# IWRL6432 register map
File version: 1.0
CPU: CM4 1.0, other endian, MPU, FPU, 3 interrupt priority bits
Registers are 32-bit, read-write, reset 0x0 unless marked. A register's access mark holds for its fields unless they carry their own. Offsets are from the block's base; [hi:lo] are bit positions; {n}, {i} and the like mark numbered series; <NAME> marks a mode.

## APP_SPI_0 — APP_SPI
Base 0x53F7F400
Same registers: APP_SPI_1 0x57F7F400
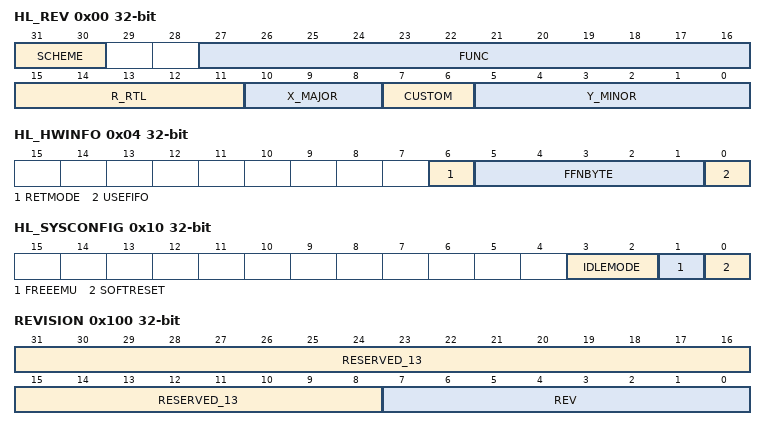
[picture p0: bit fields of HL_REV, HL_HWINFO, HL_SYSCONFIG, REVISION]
0x00 HL_REV — IP Revision Identifier (X.Y.R) Used by software to track features bugs and compatibility
  [31:30] SCHEME — [31:30] Used to distinguish between old scheme and current - (RO )
  [27:16] FUNC — [27:16] Function indicates a software compatible module family If there is no level of software compatibility a new Func number [and hence REVISION] should be assigned - (RO )
  [15:11] R_RTL — [15:11] RTL Version [R] maintained by IP design owner RTL follows a numbering such as XYRZ which are explained in this table R changes ONLY when: [1] PDS uploads occur which may have been due to spec changes [2] Bug fixes occur [3] Resets to '0' when X or Y changes Design team has an internal 'Z' [customer invisible] number which increments on every drop that happens due to DV and RTL updates Z resets to 0 when R increments - (RO )
  [10:8] X_MAJOR — [10:8] Major Revision [X] maintained by IP specification owner X changes ONLY when: [1] There is a major feature addition An example would be adding Master Mode to Utopia Level2 The Func field [or Class/Type in old PID format] will remain the same X does NOT change due to: [1] Bug fixes [2] Change in feature parameters - (RO )
  [7:6] CUSTOM — [7:6] Indicates a special version for a particular device Consequence of use may avoid use of standard Chip Support Library [CSL] / Drivers - (RO )
  [5:0] Y_MINOR — [5:0] Minor Revision [Y] maintained by IP specification owner Y changes ONLY when: [1] Features are scaled [up or down] Flexibility exists in that this feature scalability may either be represented in the Y change or a specific register in the IP that indicates which features are exactly available [2] When feature creeps from Is-Not list to Is list But this may not be the case once it sees silicon; in which case X will change Y does NOT change due to: [1] Bug fixes [2] Typos or clarifications [3] major functional/feature change/addition/deletion Instead these changes may be reflected via R S X as applicable Spec owner maintains a customer-invisible number 'S' which changes due to: [1] Typos/clarifications [2] Bug documentation Note that this bug is not due to a spec change but due to implementation Nevertheless the spec tracks the IP bugs An RTL release [say for silicon PG11] that occurs due to bug fix should document the corresponding spec number [XYS] in its release notes - (RO )
0x04 HL_HWINFO — Information about the IP module's hardware configuration i.e. typically the module's HDL generics (if any). Actual field format and encoding is up to the module's designer to decide.
  [6] RETMODE — [6:6] This bit field indicates whether the retention mode is supported using the pin PIRFFRET - (RO )
  [5:1] FFNBYTE — [5:1] FIFO number of byte generic parameter This register defines the value of FFNBYTE generic parameter only MSB bits from 8 down to 4 are taken into account - (RO )
  [0] USEFIFO — [0:0] Use of a FIFO enable: This bit field indicates if a FIFO is integrated within controller design with its management - (RO )
0x10 HL_SYSCONFIG — Clock management configuration
  [3:2] IDLEMODE — [3:2] Configuration of the local target state management mode By definition target can handle read/write transaction as long as it is out of IDLE state - (RW )
  [1] FREEEMU — [1:1] Sensitivity to emulation [debug] suspend input signal - (RW )
  [0] SOFTRESET — [0:0] Software reset [Optional] - (RW )
0x100 REVISION — This register contains the hard coded RTL revision number.
  [31:8] RESERVED_13 — [31:8] Reads returns 0 - (RO )
  [7:0] REV — [7:0] IP revision [7:4] Major revision [3:0] Minor revision Examples: 0x10 for 10 0x21 for 21 - (RO
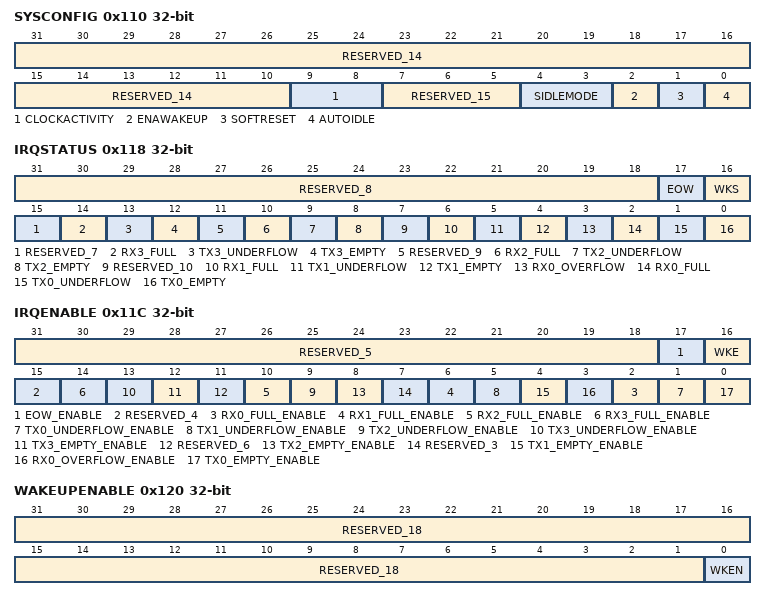
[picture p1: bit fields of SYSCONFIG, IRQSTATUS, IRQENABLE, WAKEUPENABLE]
0x110 SYSCONFIG — This register allows controlling various parameters of the OCP interface.
  [31:10] RESERVED_14 — [31:10] Reads returns 0 - (RO )
  [9:8] CLOCKACTIVITY — [9:8] Clocks activity during wake up mode period - (RW )
  [7:5] RESERVED_15 — [7:5] Reads returns 0 - (RO )
  [4:3] SIDLEMODE — [4:3] Power management - (RW )
  [2] ENAWAKEUP — [2:2] WakeUp feature control - (RW )
  [1] SOFTRESET — [1:1] Software reset During reads it always returns 0 - (RW )
  [0] AUTOIDLE — [0:0] Internal OCP Clock gating strategy - (RW )
0x114 SYSSTATUS — This register provides status information about the module excluding the interrupt status information
  [0] RESETDONE — [0:0] Internal Reset Monitoring - (RO )
0x118 IRQSTATUS — The interrupt status regroups all the status of the module internal events that can generate an interrupt
  [31:18] RESERVED_8 — [31:18] Reads returns 0 - (RO )
  [17] EOW — [17:17] End of word count event when a channel is enabled using the FIFO buffer and the channel had sent the number of SPI word defined by MCSPI_XFERLEVEL[WCNT] - (RW )
  [16] WKS — [16:16] Wake Up event in slave mode when an active control signal is detected on the SPIEN line programmed in the field MCSPI_CH0CONF[SPIENSLV] - (RW )
  [15] RESERVED_7 — [15:15] Reads returns 0 - (RO )
  [14] RX3_FULL — [14:14] Receiver register is full or almost full Only when Channel 3 is enabled - (RW )
  [13] TX3_UNDERFLOW — [13:13] Transmitter register underflow Only when Channel 3 is enabled The transmitter register is empty [not updated by Host or DMA with new data] before its time slot assignment Exception: No TX_underflow event when no data has been loaded into the transmitter register since channel has been enabled - (RW )
  [12] TX3_EMPTY — [12:12] Transmitter register is empty or almost empty Note: Enabling the channel automatically rises this event - (RW )
  [11] RESERVED_9 — [11:11] Reads returns 0 - (RO )
  [10] RX2_FULL — [10:10] Receiver register full or almost full Channel 2 - (RW )
  [9] TX2_UNDERFLOW — [9:9] Transmitter register underflow Channel 2 - (RW )
  [8] TX2_EMPTY — [8:8] Transmitter register empty or almost empty Channel 2 - (RW )
  [7] RESERVED_10 — [7:7] Reads returns 0 - (RO )
  [6] RX1_FULL — [6:6] Receiver register full or almost full Channel 1 - (RW )
  [5] TX1_UNDERFLOW — [5:5] Transmitter register underflow Channel 1 - (RW )
  [4] TX1_EMPTY — [4:4] Transmitter register empty or almost empty Channel 1 - (RW )
  [3] RX0_OVERFLOW — [3:3] Receiver register overflow [slave mode only] Channel 0 - (RW )
  [2] RX0_FULL — [2:2] Receiver register full or almost full Channel 0 - (RW )
  [1] TX0_UNDERFLOW — [1:1] Transmitter register underflow Channel 0 - (RW )
  [0] TX0_EMPTY — [0:0] Transmitter register empty or almost empty Channel 0 - (RW )
0x11C IRQENABLE — This register allows to enable/disable the module internal sources of interrupt on an event-by-event basis.
  [31:18] RESERVED_5 — [31:18] Reads return 0 - (RO )
  [17] EOW_ENABLE — [17:17] End of Word count Interrupt Enable - (RW )
  [16] WKE — [16:16] Wake Up event interrupt Enable in slave mode when an active control signal is detected on the SPIEN line programmed in the field MCSPI_CH0CONF[SPIENSLV] - (RW )
  [15] RESERVED_4 — [15:15] Reads returns 0 - (RO )
  [4n+2] RX{n}_FULL_ENABLE (n=0..3) — [{4n+2}:{4n+2}] Receiver register Full Interrupt Enable Ch {n} - (RW )
  [4n+1] TX{n}_UNDERFLOW_ENABLE (n=0..3) — [{4n+1}:{4n+1}] Transmitter register Underflow Interrupt Enable Ch {n} - (RW )
  [12] TX3_EMPTY_ENABLE — [12:12] Transmitter register Empty Interrupt Enable Ch3 - (RW )
  [11] RESERVED_6 — [11:11] Reads return 0 - (RO )
  [8] TX2_EMPTY_ENABLE — [8:8] Transmitter register Empty Interrupt Enable Ch 2 - (RW )
  [7] RESERVED_3 — [7:7] Reads return 0 - (RO )
  [4] TX1_EMPTY_ENABLE — [4:4] Transmitter register Empty Interrupt Enable Ch 1 - (RW )
  [3] RX0_OVERFLOW_ENABLE — [3:3] Receiver register Overflow Interrupt Enable Ch 0 - (RW )
  [0] TX0_EMPTY_ENABLE — [0:0] Transmitter register Empty Interrupt Enable Ch 0 - (RW )
0x120 WAKEUPENABLE — The wakeup enable register allows to enable/disable the module internal sources of wakeup on event-by-event basis.
  [31:1] RESERVED_18 — [31:1] Reads returns 0 - (RO )
  [0] WKEN — [0:0] WakeUp functionality in slave mode when an active control signal is detected on the SPIEN line programmed in the field MCSPI_CH0CONF[SPIENSLV] - (RW )
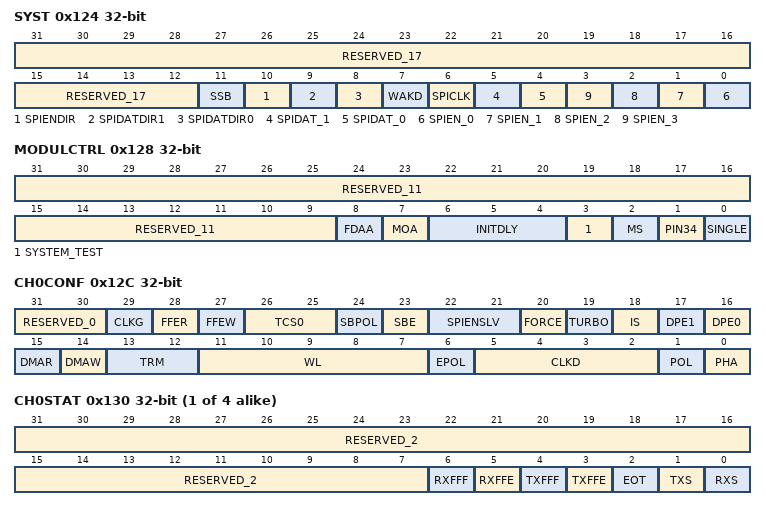
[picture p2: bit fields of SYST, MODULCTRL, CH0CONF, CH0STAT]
0x124 SYST — This register is used to check the correctness of the system interconnect either internally to peripheral bus or externally to device IO pads when the module is configured in system test (SYSTEST) mode.
  [31:12] RESERVED_17 — [31:12] Reads returns 0 - (RO )
  [11] SSB — [11:11] Set status bit - (RW )
  [10] SPIENDIR — [10:10] Set the direction of the SPIEN[3:0] lines and SPICLK line - (RW )
  [9] SPIDATDIR1 — [9:9] Set the direction of the SPIDAT[1] - (RW )
  [8] SPIDATDIR0 — [8:8] Set the direction of the SPIDAT[0] - (RW )
  [7] WAKD — [7:7] SWAKEUP output [signal data value of internal signal to system] The signal is driven high or low according to the value written into this register bit - (RW )
  [6] SPICLK — [6:6] SPICLK line [signal data value] If MCSPI_SYST[SPIENDIR] = 1 [input mode direction] this bit returns the value on the CLKSPI line [high or low] and a write into this bit has no effect If MCSPI_SYST[SPIENDIR] = 0 [output mode direction] the CLKSPI line is driven high or low according to the value written into this register - (RW )
  [5] SPIDAT_1 — [5:5] SPIDAT[1] line [signal data value] If MCSPI_SYST[SPIDATDIR1] = 0 [output mode direction] the SPIDAT[1] line is driven high or low according to the value written into this register If MCSPI_SYST[SPIDATDIR1] = 1 [input mode direction] this bit returns the value on the SPIDAT[1] line [high or low] and a write into this bit has no effect - (RW )
  [4] SPIDAT_0 — [4:4] SPIDAT[0] line [signal data value] If MCSPI_SYST[SPIDATDIR0] = 0 [output mode direction] the SPIDAT[0] line is driven high or low according to the value written into this register If MCSPI_SYST[SPIDATDIR0] = 1 [input mode direction] this bit returns the value on the SPIDAT[0] line [high or low] and a write into this bit has no effect - (RW )
  [n] SPIEN_{n} (n=0..3) — [{n}:{n}] SPIEN[{n}] line [signal data value] If MCSPI_SYST[SPIENDIR] = 0 [output mode direction] the SPIENT[{n}] line is driven high or low according to the value written into this register If MCSPI_SYST[SPIENDIR] = 1 [input mode direction] this bit returns the value on the SPIEN[{n}] line [high or low] and a write into this bit has no effect - (RW )
0x128 MODULCTRL — This register is dedicated to the configuration of the serial port interface.
  [31:9] RESERVED_11 — [31:9] Reads returns 0 - (RO )
  [8] FDAA — [8:8] FIFO DMA Address 256-bit aligned This register is used when a FIFO is managed by the module and DMA connected to the controller provides only 256 bit aligned address If this bit is set the enabled channel which uses the FIFO has its datas managed through MCSPI_DAFTX and MCSPI_DAFRX registers instead of MCSPI_TX[i] and MCSPI_RX[i] registers - (RW )
  [7] MOA — [7:7] Multiple word ocp access: This register can only be used when a channel is enabled using a FIFO It allows the system to perform multiple SPI word access for a single 32-bit OCP word access This is possible for WL < 16 - (RW )
  [6:4] INITDLY — [6:4] Initial spi delay for first transfer: This register is an option only available in SINGLE master mode The controller waits for a delay to transmit the first spi word after channel enabled and corresponding TX register filled This Delay is based on SPI output frequency clock No clock output provided to the boundary and chip select is not active in 4 pin mode within this period - (RW )
  [3] SYSTEM_TEST — [3:3] Enables the system test mode - (RW )
  [2] MS — [2:2] Master/ Slave - (RW )
  [1] PIN34 — [1:1] Pin mode selection: This register is used to configure the SPI pin mode in master or slave mode If asserted the controller only use SIMOSOMI and SPICLK clock pin for spi transfers - (RW )
  [0] SINGLE — [0:0] Single channel / Multi Channel [master mode only] - (RW )
0x12C CH0CONF — This register is dedicated to the configuration of the channel 0
  [31:30] RESERVED_0 — [31:30] read returns 0 - (RO )
  [29] CLKG — [29:29] Clock divider granularity This register defines the granularity of channel clock divider: power of two or one clock cycle granularity When this bit is set the register MCSPI_CHCTRL[EXTCLK] must be configured to reach a maximum of 4096 clock divider ratio Then The clock divider ratio is a concatenation of MCSPI_CHCONF[CLKD] and MCSPI_CHCTRL[EXTCLK] values - (RW )
  [28] FFER — [28:28] FIFO enabled for receive:Only one channel can have this bit field set - (RW )
  [27] FFEW — [27:27] FIFO enabled for Transmit:Only one channel can have this bit field set - (RW )
  [26:25] TCS0 — [26:25] Chip Select Time Control This 2-bits field defines the number of interface clock cycles between CS toggling and first or last edge of SPI clock - (RW )
  [24] SBPOL — [24:24] Start bit polarity - (RW )
  [23] SBE — [23:23] Start bit enable for SPI transfer - (RW )
  [22:21] SPIENSLV — [22:21] Channel 0 only and slave mode only: SPI slave select signal detection Reserved bits for other cases - (RW )
  [20] FORCE — [20:20] Manual SPIEN assertion to keep SPIEN active between SPI words [single channel master mode only] - (RW )
  [19] TURBO — [19:19] Turbo mode - (RW )
  [18] IS — [18:18] Input Select - (RW )
  [17] DPE1 — [17:17] Transmission Enable for data line 1 [SPIDATAGZEN[1]] - (RW )
  [16] DPE0 — [16:16] Transmission Enable for data line 0 [SPIDATAGZEN[0]] - (RW )
  [15] DMAR — [15:15] DMA Read request The DMA Read request line is asserted when the channel is enabled and a new data is available in the receive register of the channel The DMA Read request line is deasserted on read completion of the receive register of the channel - (RW )
  [14] DMAW — [14:14] DMA Write request The DMA Write request line is asserted when The channel is enabled and the transmitter register of the channel is empty The DMA Write request line is deasserted on load completion of the transmitter register of the channel - (RW )
  [13:12] TRM — [13:12] Transmit/Receive modes - (RW )
  [11:7] WL — [11:7] SPI word length - (RW )
  [6] EPOL — [6:6] SPIEN polarity - (RW )
  [5:2] CLKD — [5:2] Frequency divider for SPICLK [only when the module is a Master SPI device] A programmable clock divider divides the SPI reference clock [CLKSPIREF] with a 4-bit value and results in a new clock SPICLK available to shift-in and shift-out data By default the clock divider ratio has a power of two granularity when MCSPI_CHCONF[CLKG] is cleared Otherwise this register is the 4 LSB bit of a 12-bit register concatenated with clock divider extension MCSPI_CHCTRL[EXTCLK] registerThe value description below defines the clock ratio when MCSPI_CHCONF[CLKG] is set to 0 - (RW )
  [1] POL — [1:1] SPICLK polarity - (RW )
  [0] PHA — [0:0] SPICLK phase - (RW )
{0x130+0x14*i} CH{i}STAT (i=0..3) — This register provides status information about transmitter and receiver registers of channel {i}
  [31:7] RESERVED_2 — [31:7] Read returns 0 - (RO )
  [6] RXFFF — [6:6] Channel "i" FIFO Receive Buffer Full Status - (RO )
  [5] RXFFE — [5:5] Channel "i" FIFO Receive Buffer Empty Status - (RO )
  [4] TXFFF — [4:4] Channel "i" FIFO Transmit Buffer Full Status - (RO )
  [3] TXFFE — [3:3] Channel "i" FIFO Transmit Buffer Empty Status - (RO )
  [2] EOT — [2:2] Channel "i" End of transfer Status The definitions of beginning and end of transfer vary with master versus slave and the transfer format [Transmit/Receive modes Turbo mode] See dedicated chapters for details - (RO )
  [1] TXS — [1:1] Channel "i" Transmitter Register Status - (RO )
  [0] RXS — [0:0] Channel "i" Receiver Register Status - (RO )
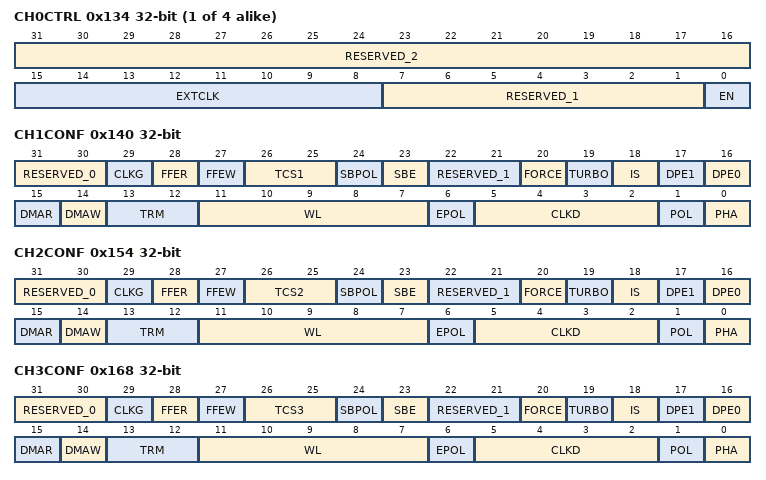
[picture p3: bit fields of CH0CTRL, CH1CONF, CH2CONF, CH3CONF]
{0x134+0x14*i} CH{i}CTRL (i=0..3) — This register is dedicated to enable the channel {i}
  [31:16] RESERVED_2 — [31:16] Read returns 0 - (RO )
  [15:8] EXTCLK — [15:8] Clock ratio extension: This register is used to concatenate with MCSPI_CHCONF[CLKD] register for clock ratio only when granularity is one clock cycle [MCSPI_CHCONF[CLKG] set to 1] Then the max value reached is 4096 clock divider ratio - (RW )
  [7:1] RESERVED_1 — [7:1] Read returns 0 - (RO )
  [0] EN — [0:0] Channel Enable - (RW )
{0x138+0x14*i} TX{i} (i=0..3) — This register contains a single SPI word to transmit on the serial link what ever SPI word length is.
  [31:0] TDATA — [31:0] Channel {i} Data to transmit - (RW )
{0x13C+0x14*i} RX{i} (i=0..3) — This register contains a single SPI word received through the serial link what ever SPI word length is.
  [31:0] RDATA — [31:0] Channel {i} Received Data - (RO )
0x140 CH1CONF — This register is dedicated to the configuration of the channel.
  [31:30] RESERVED_0 — [31:30] read returns 0 - (RO )
  [29] CLKG — [29:29] Clock divider granularity This register defines the granularity of channel clock divider: power of two or one clock cycle granularity When this bit is set the register MCSPI_CHCTRL[EXTCLK] must be configured to reach a maximum of 4096 clock divider ratio Then The clock divider ratio is a concatenation of MCSPI_CHCONF[CLKD] and MCSPI_CHCTRL[EXTCLK] values - (RW )
  [28] FFER — [28:28] FIFO enabled for receive:Only one channel can have this bit field set - (RW )
  [27] FFEW — [27:27] FIFO enabled for Transmit:Only one channel can have this bit field set - (RW )
  [26:25] TCS1 — [26:25] Chip Select Time Control This 2-bits field defines the number of interface clock cycles between CS toggling and first or last edge of SPI clock - (RW )
  [24] SBPOL — [24:24] Start bit polarity - (RW )
  [23] SBE — [23:23] Start bit enable for SPI transfer - (RW )
  [22:21] RESERVED_1 — [22:21] read returns 0 - (RO )
  [20] FORCE — [20:20] Manual SPIEN assertion to keep SPIEN active between SPI words [single channel master mode only] - (RW )
  [19] TURBO — [19:19] Turbo mode - (RW )
  [18] IS — [18:18] Input Select - (RW )
  [17] DPE1 — [17:17] Transmission Enable for data line 1 [SPIDATAGZEN[1]] - (RW )
  [16] DPE0 — [16:16] Transmission Enable for data line 0 [SPIDATAGZEN[0]] - (RW )
  [15] DMAR — [15:15] DMA Read request The DMA Read request line is asserted when the channel is enabled and a new data is available in the receive register of the channel The DMA Read request line is deasserted on read completion of the receive register of the channel - (RW )
  [14] DMAW — [14:14] DMA Write request The DMA Write request line is asserted when The channel is enabled and the transmitter register of the channel is empty The DMA Write request line is deasserted on load completion of the transmitter register of the channel - (RW )
  [13:12] TRM — [13:12] Transmit/Receive modes - (RW )
  [11:7] WL — [11:7] SPI word length - (RW )
  [6] EPOL — [6:6] SPIEN polarity - (RW )
  [5:2] CLKD — [5:2] Frequency divider for SPICLK [only when the module is a Master SPI device] A programmable clock divider divides the SPI reference clock [CLKSPIREF] with a 4-bit value and results in a new clock SPICLK available to shift-in and shift-out data By default the clock divider ratio has a power of two granularity when MCSPI_CHCONF[CLKG] is cleared Otherwise this register is the 4 LSB bit of a 12-bit register concatenated with clock divider extension MCSPI_CHCTRL[EXTCLK] registerThe value description below defines the clock ratio when MCSPI_CHCONF[CLKG] is set to 0 - (RW )
  [1] POL — [1:1] SPICLK polarity - (RW )
  [0] PHA — [0:0] SPICLK phase - (RW )
0x154 CH2CONF — This register is dedicated to the configuration of the channel 2
  [31:30] RESERVED_0 — [31:30] read returns 0 - (RO )
  [29] CLKG — [29:29] Clock divider granularity This register defines the granularity of channel clock divider: power of two or one clock cycle granularity When this bit is set the register MCSPI_CHCTRL[EXTCLK] must be configured to reach a maximum of 4096 clock divider ratio Then The clock divider ratio is a concatenation of MCSPI_CHCONF[CLKD] and MCSPI_CHCTRL[EXTCLK] values - (RW )
  [28] FFER — [28:28] FIFO enabled for receive:Only one channel can have this bit field set - (RW )
  [27] FFEW — [27:27] FIFO enabled for Transmit:Only one channel can have this bit field set - (RW )
  [26:25] TCS2 — [26:25] Chip Select Time Control This 2-bits field defines the number of interface clock cycles between CS toggling and first or last edge of SPI clock - (RW )
  [24] SBPOL — [24:24] Start bit polarity - (RW )
  [23] SBE — [23:23] Start bit enable for SPI transfer - (RW )
  [22:21] RESERVED_1 — [22:21] read returns 0 - (RO )
  [20] FORCE — [20:20] Manual SPIEN assertion to keep SPIEN active between SPI words [single channel master mode only] - (RW )
  [19] TURBO — [19:19] Turbo mode - (RW )
  [18] IS — [18:18] Input Select - (RW )
  [17] DPE1 — [17:17] Transmission Enable for data line 1 [SPIDATAGZEN[1]] - (RW )
  [16] DPE0 — [16:16] Transmission Enable for data line 0 [SPIDATAGZEN[0]] - (RW )
  [15] DMAR — [15:15] DMA Read request The DMA Read request line is asserted when the channel is enabled and a new data is available in the receive register of the channel The DMA Read request line is deasserted on read completion of the receive register of the channel - (RW )
  [14] DMAW — [14:14] DMA Write request The DMA Write request line is asserted when The channel is enabled and the transmitter register of the channel is empty The DMA Write request line is deasserted on load completion of the transmitter register of the channel - (RW )
  [13:12] TRM — [13:12] Transmit/Receive modes - (RW )
  [11:7] WL — [11:7] SPI word length - (RW )
  [6] EPOL — [6:6] SPIEN polarity - (RW )
  [5:2] CLKD — [5:2] Frequency divider for SPICLK [only when the module is a Master SPI device] A programmable clock divider divides the SPI reference clock [CLKSPIREF] with a 4-bit value and results in a new clock SPICLK available to shift-in and shift-out data By default the clock divider ratio has a power of two granularity when MCSPI_CHCONF[CLKG] is cleared Otherwise this register is the 4 LSB bit of a 12-bit register concatenated with clock divider extension MCSPI_CHCTRL[EXTCLK] registerThe value description below defines the clock ratio when MCSPI_CHCONF[CLKG] is set to 0 - (RW )
  [1] POL — [1:1] SPICLK polarity - (RW )
  [0] PHA — [0:0] SPICLK phase - (RW )
0x168 CH3CONF — This register is dedicated to the configuration of the channel 3
  [31:30] RESERVED_0 — [31:30] read returns 0 - (RO )
  [29] CLKG — [29:29] Clock divider granularity This register defines the granularity of channel clock divider: power of two or one clock cycle granularity When this bit is set the register MCSPI_CHCTRL[EXTCLK] must be configured to reach a maximum of 4096 clock divider ratio Then The clock divider ratio is a concatenation of MCSPI_CHCONF[CLKD] and MCSPI_CHCTRL[EXTCLK] values - (RW )
  [28] FFER — [28:28] FIFO enabled for receive:Only one channel can have this bit field set - (RW )
  [27] FFEW — [27:27] FIFO enabled for Transmit:Only one channel can have this bit field set - (RW )
  [26:25] TCS3 — [26:25] Chip Select Time Control This 2-bits field defines the number of interface clock cycles between CS toggling and first or last edge of SPI clock - (RW )
  [24] SBPOL — [24:24] Start bit polarity - (RW )
  [23] SBE — [23:23] Start bit enable for SPI transfer - (RW )
  [22:21] RESERVED_1 — [22:21] read returns 0 - (RO )
  [20] FORCE — [20:20] Manual SPIEN assertion to keep SPIEN active between SPI words [single channel master mode only] - (RW )
  [19] TURBO — [19:19] Turbo mode - (RW )
  [18] IS — [18:18] Input Select - (RW )
  [17] DPE1 — [17:17] Transmission Enable for data line 1 [SPIDATAGZEN[1]] - (RW )
  [16] DPE0 — [16:16] Transmission Enable for data line 0 [SPIDATAGZEN[0]] - (RW )
  [15] DMAR — [15:15] DMA Read request The DMA Read request line is asserted when the channel is enabled and a new data is available in the receive register of the channel The DMA Read request line is deasserted on read completion of the receive register of the channel - (RW )
  [14] DMAW — [14:14] DMA Write request The DMA Write request line is asserted when The channel is enabled and the transmitter register of the channel is empty The DMA Write request line is deasserted on load completion of the transmitter register of the channel - (RW )
  [13:12] TRM — [13:12] Transmit/Receive modes - (RW )
  [11:7] WL — [11:7] SPI word length - (RW )
  [6] EPOL — [6:6] SPIEN polarity - (RW )
  [5:2] CLKD — [5:2] Frequency divider for SPICLK [only when the module is a Master SPI device] A programmable clock divider divides the SPI reference clock [CLKSPIREF] with a 4-bit value and results in a new clock SPICLK available to shift-in and shift-out data By default the clock divider ratio has a power of two granularity when MCSPI_CHCONF[CLKG] is cleared Otherwise this register is the 4 LSB bit of a 12-bit register concatenated with clock divider extension MCSPI_CHCTRL[EXTCLK] registerThe value description below defines the clock ratio when MCSPI_CHCONF[CLKG] is set to 0 - (RW )
  [1] POL — [1:1] SPICLK polarity - (RW )
  [0] PHA — [0:0] SPICLK phase - (RW )
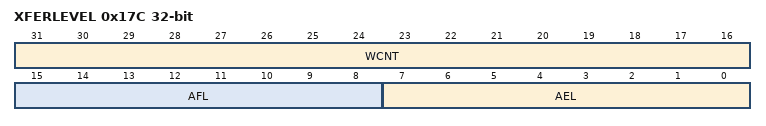
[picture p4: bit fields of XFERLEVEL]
0x17C XFERLEVEL — This register provides transfer levels needed while using FIFO buffer during transfer.
  [31:16] WCNT — [31:16] Spi word counterThis register holds the programmable value of number of SPI word to be transferred on channel which is using the FIFO bufferWhen transfer had started a read back in this register returns the current SPI word transfer index - (RW )
  [15:8] AFL — [15:8] Buffer Almost Full This register holds the programmable almost full level value used to determine almost full buffer condition If the user wants an interrupt or a DMA read request to be issued during a receive operation when the data buffer holds at least n bytes then the buffer MCSPI_MODULCTRL[AFL] must be set with n-1The size of this register is defined by the generic parameter FFNBYTE - (RW )
  [7:0] AEL — [7:0] Buffer Almost EmptyThis register holds the programmable almost empty level value used to determine almost empty buffer condition If the user wants an interrupt or a DMA write request to be issued during a transmit operation when the data buffer is able to receive n bytes then the buffer MCSPI_MODULCTRL[AEL] must be set with n-1 - (RW )
0x180 DAFTX — This register contains the SPI words to transmit on the serial link when FIFO used and DMA address is aligned on 256 bit.This register is an image of one of MCSPI_TX(i) register corresponding to the channel which have its FIFO enabled.
  [31:0] DAFTDATA — [31:0] FIFO Data to transmit with DMA 256 bit aligned address This Register is only is used when MCSPI_MODULCTRL[FDAA] is set to "1" and only one of the MCSPI_CH[i]CONF[FFEW] of enabled channels is set If these conditions are not respected any access to this register return a null value - (RW )
0x1A0 DAFRX — This register contains the SPI words to received on the serial link when FIFO used and DMA address is aligned on 256 bit.This register is an image of one of MCSPI_RX(i) register corresponding to the channel which have its FIFO enabled.
  [31:0] DAFRDATA — [31:0] FIFO Data to transmit with DMA 256 bit aligned address This Register is only is used when MCSPI_MODULCTRL[FDAA] is set to "1" and only one of the MCSPI_CH[i]CONF[FFEW] of enabled channels is set If these conditions are not respected any access to this register return a null value - (RO )
